# PCIE_CFG_TYPE0 register map
Vendor: Texas Instruments
Peripheral module from a debugger description file (folder 66AK2G0x_66AK2G1x).
Registers are 32-bit, access per field, reset 0x0 unless marked. A register's access mark holds for its fields unless they carry their own. Offsets are as the file gives them; lines under a group give offsets from that group; [hi:lo] are bit positions; {n}, {i} and the like mark numbered series; 'fields as' and 'values as' point back to an identical list; <NAME> marks a mode.

## PCIE_CFG_TYPE0
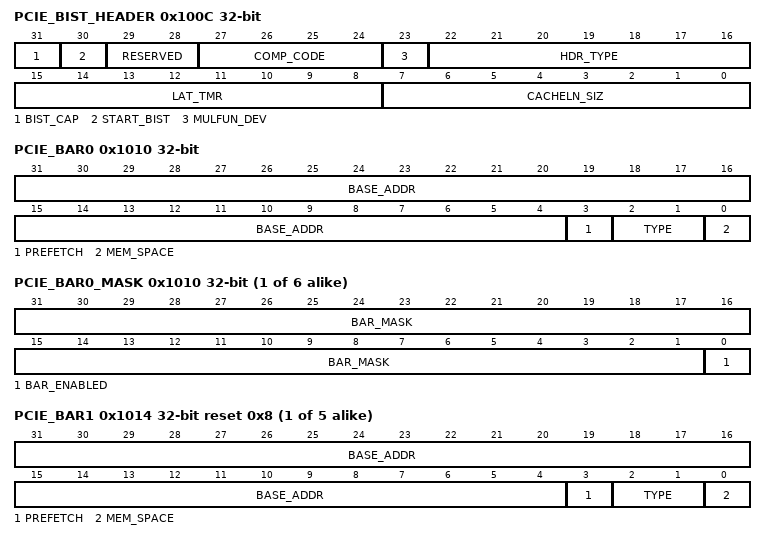
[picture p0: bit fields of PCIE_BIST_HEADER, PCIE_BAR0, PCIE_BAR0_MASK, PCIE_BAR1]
0x100C PCIE_BIST_HEADER
  [31] BIST_CAP ro — Returns a one for BIST capability and zero otherwise. Not supported by PCIESS.
  [30] START_BIST ro — Write a one to start BIST. Not supported by PCIESS.
  [29:28] RESERVED ro — Reads return 0 and writes have no effect.
  [27:24] COMP_CODE ro — Completion code. Not supported by PCIESS.
  [23] MULFUN_DEV ro — Returns 1 if it is a multi-function device. Writable from internal bus interface.
  [22:16] HDR_TYPE ro — Configuration header format.
  [15:8] LAT_TMR ro — Not applicable in PCIe
  [7:0] CACHELN_SIZ rw — Not applicable in PCIe
0x1010 PCIE_BAR0
  [31:4] BASE_ADDR rw — Base Address. Based on the configuration of Register, not all bits may be writable.
  [3] PREFETCH ro — For memory BARs, it indicates whether the region is prefetchable. Writable from internal bus interface. For I/O Bars, it is used as second least significant bit (LSB) of the base address. Writable from internal bus interface.
  [2:1] TYPE ro — For memory BARs, they determine the BAR type. Writable from internal bus interface. For I/O BARs, bit 2 is the least significant bit (LSB) of the base address and bit 1 is 0. Writable from internal bus interface.
  [0] MEM_SPACE ro — Writable from internal bus interface.
{0x1010+4i} PCIE_BAR{i}_MASK wo (i=0..5)
  [31:1] BAR_MASK — Indicates whichPCIE_BAR{i} bits to mask (non-writeable) from host, which determines the size of the BAR. The bits are writeable only, not readable.
  [0] BAR_ENABLED — PCIE_BAR{i} Enable. The bit is writeable only, not readable.
{0x1010+4i} PCIE_BAR{i} reset 0x8 (i=1..5)
  fields as PCIE_BAR0
0x102C PCIE_SUBSYS_VNDR_ID ro reset 0x10000
  [31:0] REV — TI internal data. Identifies revision of peripheral.
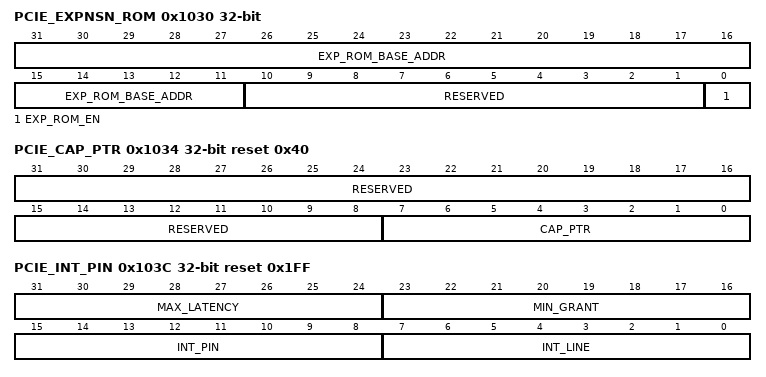
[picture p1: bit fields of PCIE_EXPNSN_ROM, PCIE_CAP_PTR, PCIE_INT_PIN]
0x1030 PCIE_EXPNSN_ROM ro
  [31:11] EXP_ROM_BASE_ADDR — Address of Expansion ROM
  [10:1] RESERVED — Reads return 0 and writes have no effect.
  [0] EXP_ROM_EN — Expansion ROM Enable
0x1034 PCIE_CAP_PTR ro reset 0x40
  [31:8] RESERVED — Reads return 0 and writes have no effect.
  [7:0] CAP_PTR — First Capability Pointer. By default, it points to Power Management Capability structure. Writable from internal bus interface.
0x103C PCIE_INT_PIN reset 0x1FF
  [31:24] MAX_LATENCY ro — Not applicable to PCI Express.
  [23:16] MIN_GRANT ro — Not applicable to PCI Express.
  [15:8] INT_PIN ro — Interrupt Pin. It identifies the legacy interrupt message that the device uses. For single function configuration, the core only uses INTA. This register is writable through internal bus interface.
  [7:0] INT_LINE rw — Interrupt Line. Value is system software specified.
